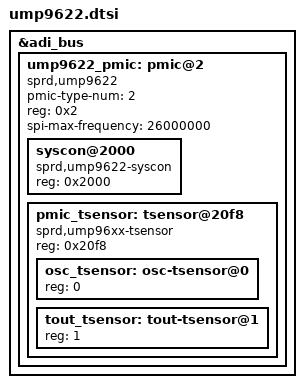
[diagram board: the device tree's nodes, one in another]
/*
 * UNISOC UMP9622 PMIC dts file
 *
 * Copyright (C) 2020, UNISOC Communications Inc.
 *
 * SPDX-License-Identifier: (GPL-2.0+ OR MIT)
 */

&adi_bus {
	ump9622_pmic: pmic@2 {
		compatible = "sprd,ump9622";
		pmic-type-num = <2>;
		reg = <0x2>;
		spi-max-frequency = <26000000>;
		#address-cells = <1>;
		#size-cells = <0>;

		syscon@2000 {
			compatible = "sprd,ump9622-syscon";
			reg = <0x2000>;
		};
		pmic_tsensor: tsensor@20f8 {
			compatible = "sprd,ump96xx-tsensor";
			#thermal-sensor-cells = <1>;
			reg = <0x20f8>;
			#address-cells = <1>;
			#size-cells = <0>;

			osc_tsensor: osc-tsensor@0{
				reg = <0>;
			};

			tout_tsensor: tout-tsensor@1{
				reg = <1>;
			};
		};

	};
};
